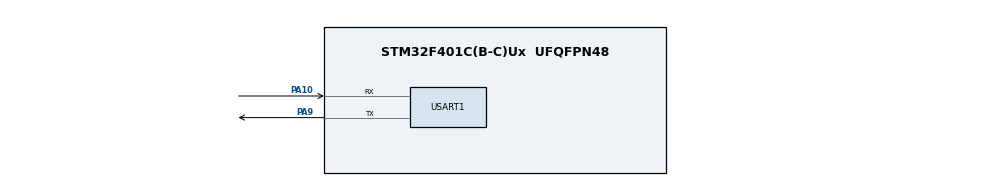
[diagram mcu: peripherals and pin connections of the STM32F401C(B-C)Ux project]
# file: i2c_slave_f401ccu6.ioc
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Mcu.Family=STM32F4
Mcu.Name=STM32F401C(B-C)Ux
Mcu.Package=UFQFPN48
NVIC.PriorityGroup=NVIC_PRIORITYGROUP_4
PA10.Mode=Asynchronous
PA10.Signal=USART1_RX
PA13.Mode=Serial_Wire
PA13.Signal=SYS_JTMS-SWDIO
PA14.Mode=Serial_Wire
PA14.Signal=SYS_JTCK-SWCLK
PA9.Mode=Asynchronous
PA9.Signal=USART1_TX
PH0\ -\ OSC_IN.Mode=HSE-External-Oscillator
PH0\ -\ OSC_IN.Signal=RCC_OSC_IN
PH1\ -\ OSC_OUT.Mode=HSE-External-Oscillator
PH1\ -\ OSC_OUT.Signal=RCC_OSC_OUT
ProjectManager.HeapSize=0x200
ProjectManager.StackSize=0x400
ProjectManager.TargetToolchain=STM32CubeIDE
RCC.48MHZClocksFreq_Value=42000000
RCC.AHBFreq_Value=84000000
RCC.APB1CLKDivider=RCC_HCLK_DIV2
RCC.APB1Freq_Value=42000000
RCC.APB1TimFreq_Value=84000000
RCC.APB2Freq_Value=84000000
RCC.APB2TimFreq_Value=84000000
RCC.CortexFreq_Value=84000000
RCC.HCLKFreq_Value=84000000
RCC.HSE_VALUE=25000000
RCC.HSI_VALUE=16000000
RCC.LSE_VALUE=32768
RCC.PLLM=8
RCC.PLLN=84
RCC.SYSCLKFreq_VALUE=84000000
RCC.SYSCLKSource=RCC_SYSCLKSOURCE_PLLCLK
RCC.VCOOutputFreq_Value=168000000
USART1.VirtualMode=VM_ASYNC
board=custom

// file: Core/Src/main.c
/* USER CODE BEGIN Header */
/**
 ******************************************************************************
 * @file           : main.c
 * @brief          : Main program body
 ******************************************************************************
 * @attention
 *
 * Copyright (c) 2024 STMicroelectronics.
 * All rights reserved.
 *
 * This software is licensed under terms that can be found in the LICENSE file
 * in the root directory of this software component.
 * If no LICENSE file comes with this software, it is provided AS-IS.
 *
 ******************************************************************************
 */
/* USER CODE END Header */
#include "main.h"

/* USER CODE BEGIN Includes */
#include "i2c_bitbang.h"
#include "myuart.h"
/* USER CODE END Includes */

void SystemClock_Config(void);
static void MX_GPIO_Init(void);
static void MX_USART1_UART_Init(void);

int main(void)
{

  /* MCU Configuration--------------------------------------------------------*/

  /* Reset of all peripherals, Initializes the Flash interface and the Systick. */
  LL_APB2_GRP1_EnableClock(LL_APB2_GRP1_PERIPH_SYSCFG);
  LL_APB1_GRP1_EnableClock(LL_APB1_GRP1_PERIPH_PWR);

  /* System interrupt init*/
  NVIC_SetPriorityGrouping(NVIC_PRIORITYGROUP_4);

  /* SysTick_IRQn interrupt configuration */
  NVIC_SetPriority(SysTick_IRQn, NVIC_EncodePriority(NVIC_GetPriorityGrouping(), 15, 0));

  /* Configure the system clock */
  SystemClock_Config();

  /* Initialize all configured peripherals */
  MX_GPIO_Init();
  MX_USART1_UART_Init();
  /* USER CODE BEGIN 2 */
  I2C_Bitbang_Init();
  uart_printf("slave\r\n");
  DWT_Clock_Enable();
  /* USER CODE END 2 */

  /* Infinite loop */
  while (1)
  {

  }
}

void SystemClock_Config(void)
{
  LL_FLASH_SetLatency(LL_FLASH_LATENCY_2);
  while (LL_FLASH_GetLatency() != LL_FLASH_LATENCY_2)
  {
  }
  LL_PWR_SetRegulVoltageScaling(LL_PWR_REGU_VOLTAGE_SCALE2);
  LL_RCC_HSI_SetCalibTrimming(16);
  LL_RCC_HSI_Enable();

  /* Wait till HSI is ready */
  while (LL_RCC_HSI_IsReady() != 1)
  {
  }
  LL_RCC_PLL_ConfigDomain_SYS(LL_RCC_PLLSOURCE_HSI, LL_RCC_PLLM_DIV_8, 84, LL_RCC_PLLP_DIV_2);
  LL_RCC_PLL_Enable();

  /* Wait till PLL is ready */
  while (LL_RCC_PLL_IsReady() != 1)
  {
  }
  while (LL_PWR_IsActiveFlag_VOS() == 0)
  {
  }
  LL_RCC_SetAHBPrescaler(LL_RCC_SYSCLK_DIV_1);
  LL_RCC_SetAPB1Prescaler(LL_RCC_APB1_DIV_2);
  LL_RCC_SetAPB2Prescaler(LL_RCC_APB2_DIV_1);
  LL_RCC_SetSysClkSource(LL_RCC_SYS_CLKSOURCE_PLL);

  /* Wait till System clock is ready */
  while (LL_RCC_GetSysClkSource() != LL_RCC_SYS_CLKSOURCE_STATUS_PLL)
  {
  }
  LL_Init1msTick(84000000);
  LL_SetSystemCoreClock(84000000);
  LL_RCC_SetTIMPrescaler(LL_RCC_TIM_PRESCALER_TWICE);
}

static void MX_USART1_UART_Init(void)
{

  LL_USART_InitTypeDef USART_InitStruct = {0};

  LL_GPIO_InitTypeDef GPIO_InitStruct = {0};

  /* Peripheral clock enable */
  LL_APB2_GRP1_EnableClock(LL_APB2_GRP1_PERIPH_USART1);

  LL_AHB1_GRP1_EnableClock(LL_AHB1_GRP1_PERIPH_GPIOA);
  /**USART1 GPIO Configuration
  PA9   ------> USART1_TX
  PA10   ------> USART1_RX
  */
  GPIO_InitStruct.Pin = LL_GPIO_PIN_9 | LL_GPIO_PIN_10;
  GPIO_InitStruct.Mode = LL_GPIO_MODE_ALTERNATE;
  GPIO_InitStruct.Speed = LL_GPIO_SPEED_FREQ_VERY_HIGH;
  GPIO_InitStruct.OutputType = LL_GPIO_OUTPUT_PUSHPULL;
  GPIO_InitStruct.Pull = LL_GPIO_PULL_NO;
  GPIO_InitStruct.Alternate = LL_GPIO_AF_7;
  LL_GPIO_Init(GPIOA, &GPIO_InitStruct);

  USART_InitStruct.BaudRate = 115200;
  USART_InitStruct.DataWidth = LL_USART_DATAWIDTH_8B;
  USART_InitStruct.StopBits = LL_USART_STOPBITS_1;
  USART_InitStruct.Parity = LL_USART_PARITY_NONE;
  USART_InitStruct.TransferDirection = LL_USART_DIRECTION_TX_RX;
  USART_InitStruct.HardwareFlowControl = LL_USART_HWCONTROL_NONE;
  USART_InitStruct.OverSampling = LL_USART_OVERSAMPLING_16;
  LL_USART_Init(USART1, &USART_InitStruct);
  LL_USART_ConfigAsyncMode(USART1);
  LL_USART_Enable(USART1);
}

static void MX_GPIO_Init(void)
{

  /* GPIO Ports Clock Enable */
  LL_AHB1_GRP1_EnableClock(LL_AHB1_GRP1_PERIPH_GPIOH);
  LL_AHB1_GRP1_EnableClock(LL_AHB1_GRP1_PERIPH_GPIOA);

}

void Error_Handler(void)
{
  __disable_irq();
  while (1)
  {
  }
}
